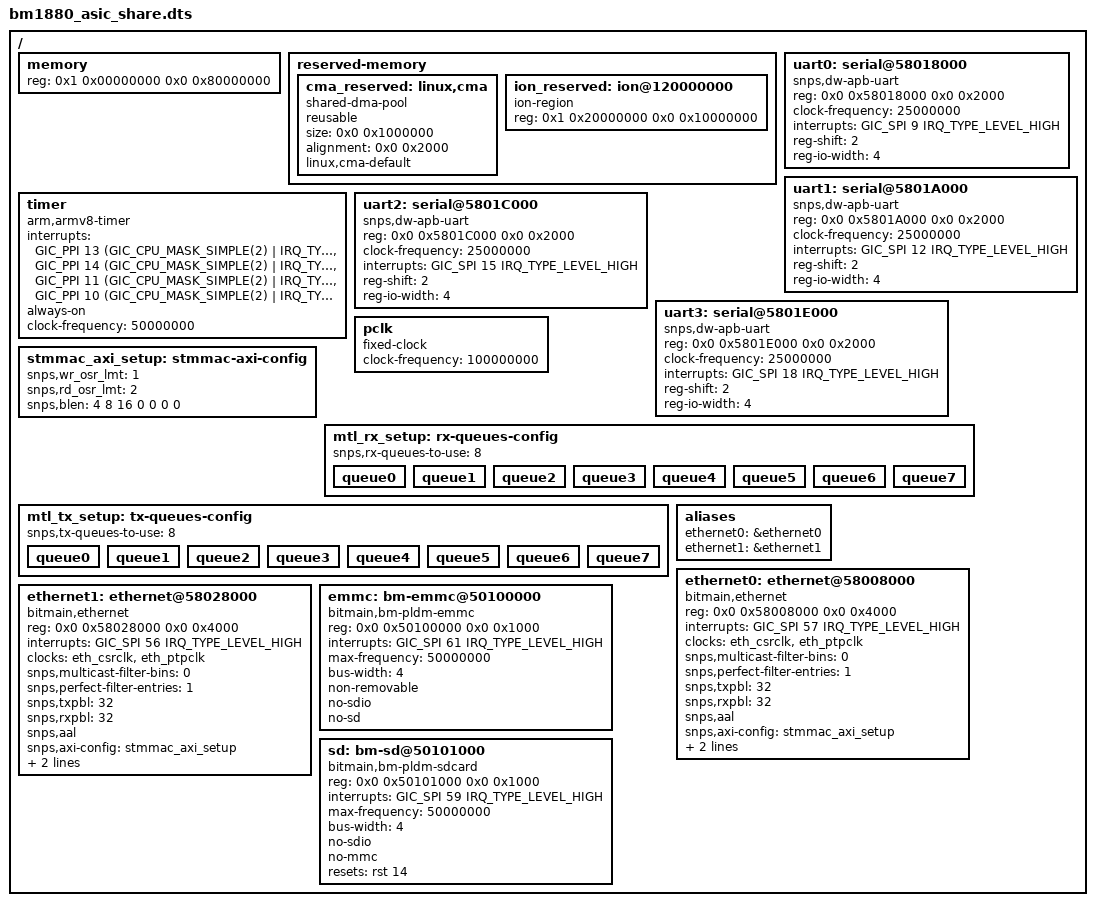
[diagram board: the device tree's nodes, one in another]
/dts-v1/;

#include "bm1880.dtsi"



/ {
	memory {
		reg = <0x1 0x00000000 0x0 0x80000000>;
		device_type = "memory";
	};

	reserved-memory {
		#address-cells = <0x2>;
		#size-cells = <0x2>;
		ranges;

		cma_reserved: linux,cma {
			compatible = "shared-dma-pool";
			reusable;
			size = <0x0 0x1000000>; // 16MB
			alignment = <0x0 0x2000>; // 8KB
			linux,cma-default;
		};

		ion_reserved: ion@120000000 {
			compatible = "ion-region";
			reg = <0x1 0x20000000 0x0 0x10000000>; // 256MB
		};
	};

	timer {
		interrupts = <GIC_PPI 13 (GIC_CPU_MASK_SIMPLE(2) | IRQ_TYPE_LEVEL_LOW)>,
			<GIC_PPI 14 (GIC_CPU_MASK_SIMPLE(2) | IRQ_TYPE_LEVEL_LOW)>,
			<GIC_PPI 11 (GIC_CPU_MASK_SIMPLE(2) | IRQ_TYPE_LEVEL_LOW)>,
			<GIC_PPI 10 (GIC_CPU_MASK_SIMPLE(2) | IRQ_TYPE_LEVEL_LOW)>;
		always-on;
		clock-frequency = <50000000>;
		compatible = "arm,armv8-timer";
	};

	uart0: serial@58018000 {
		compatible = "snps,dw-apb-uart";
		reg = <0x0 0x58018000 0x0 0x2000>;
		clock-frequency = <25000000>;
		interrupts = <GIC_SPI 9 IRQ_TYPE_LEVEL_HIGH>;
		reg-shift = <2>;
		reg-io-width = <4>;
		//dmas = <&dmac 10 1 1 /* read channel */
		//	&dmac 11 1 1>; /* write channel */
		//dma-names = "rx", "tx";
	};

	uart1: serial@5801A000 {
		compatible = "snps,dw-apb-uart";
		reg = <0x0 0x5801A000 0x0 0x2000>;
		clock-frequency = <25000000>;
		interrupts = <GIC_SPI 12 IRQ_TYPE_LEVEL_HIGH>;
		reg-shift = <2>;
		reg-io-width = <4>;
	};

	uart2: serial@5801C000 {
		compatible = "snps,dw-apb-uart";
		reg = <0x0 0x5801C000 0x0 0x2000>;
		clock-frequency = <25000000>;
		interrupts = <GIC_SPI 15 IRQ_TYPE_LEVEL_HIGH>;
		reg-shift = <2>;
		reg-io-width = <4>;
	};

	uart3: serial@5801E000 {
		compatible = "snps,dw-apb-uart";
		reg = <0x0 0x5801E000 0x0 0x2000>;
		clock-frequency = <25000000>;
		interrupts = <GIC_SPI 18 IRQ_TYPE_LEVEL_HIGH>;
		reg-shift = <2>;
		reg-io-width = <4>;
	};


	pclk: pclk {
		#clock-cells = <0>;
		compatible = "fixed-clock";
		clock-frequency = <100000000>;
	};

	stmmac_axi_setup: stmmac-axi-config {
		snps,wr_osr_lmt = <1>;
		snps,rd_osr_lmt = <2>;
		snps,blen = <4 8 16 0 0 0 0>;
	};

	mtl_rx_setup: rx-queues-config {
		snps,rx-queues-to-use = <8>;
		queue0 {};
		queue1 {};
		queue2 {};
		queue3 {};
		queue4 {};
		queue5 {};
		queue6 {};
		queue7 {};
	};

	mtl_tx_setup: tx-queues-config {
		snps,tx-queues-to-use = <8>;
		queue0 {};
		queue1 {};
		queue2 {};
		queue3 {};
		queue4 {};
		queue5 {};
		queue6 {};
		queue7 {};
	};

	aliases {
		ethernet0 = &ethernet0;
		ethernet1 = &ethernet1;
	};

	ethernet0: ethernet@58008000 {
		compatible = "bitmain,ethernet";
		reg = <0x0 0x58008000 0x0 0x4000>;
		interrupts = <GIC_SPI 57 IRQ_TYPE_LEVEL_HIGH>;
		interrupt-names = "macirq";
		clock-names = "stmmaceth", "ptp_ref";
		clocks = <&eth_csrclk>, <&eth_ptpclk> ;

		/* no hash filter and perfect filter support */
		snps,multicast-filter-bins = <0>;
		snps,perfect-filter-entries = <1>;

		snps,txpbl = <32>;
		snps,rxpbl = <32>;
		snps,aal;

		snps,axi-config = <&stmmac_axi_setup>;
		snps,mtl-rx-config = <&mtl_rx_setup>;
		snps,mtl-tx-config = <&mtl_tx_setup>;

	};

	ethernet1: ethernet@58028000 {
		compatible = "bitmain,ethernet";
		reg = <0x0 0x58028000 0x0 0x4000>;
		interrupts = <GIC_SPI 56 IRQ_TYPE_LEVEL_HIGH>;
		interrupt-names = "macirq";
		clock-names = "stmmaceth", "ptp_ref";
		clocks = <&eth_csrclk>, <&eth_ptpclk> ;

		/* no hash filter and perfect filter support */
		snps,multicast-filter-bins = <0>;
		snps,perfect-filter-entries = <1>;

		snps,txpbl = <32>;
		snps,rxpbl = <32>;
		snps,aal;

		snps,axi-config = <&stmmac_axi_setup>;
		snps,mtl-rx-config = <&mtl_rx_setup>;
		snps,mtl-tx-config = <&mtl_tx_setup>;

	};

	emmc:bm-emmc@50100000 {
		compatible = "bitmain,bm-pldm-emmc";
		reg = <0x0 0x50100000 0x0 0x1000>;
		reg-names = "core_mem";
		interrupts = <GIC_SPI 61 IRQ_TYPE_LEVEL_HIGH>;
		max-frequency = <50000000>;
		bus-width = <4>;
		non-removable;
		no-sdio;
		no-sd;
	};

	sd:bm-sd@50101000 {
		compatible = "bitmain,bm-pldm-sdcard";
		reg = <0x0 0x50101000 0x0 0x1000>;
		reg-names = "core_mem";
		interrupts = <GIC_SPI 59 IRQ_TYPE_LEVEL_HIGH>;
		max-frequency = <50000000>;
		bus-width = <4>;
		no-sdio;
		no-mmc;
		resets = <&rst 14>;
		reset-names = "sdio";
	};

};
